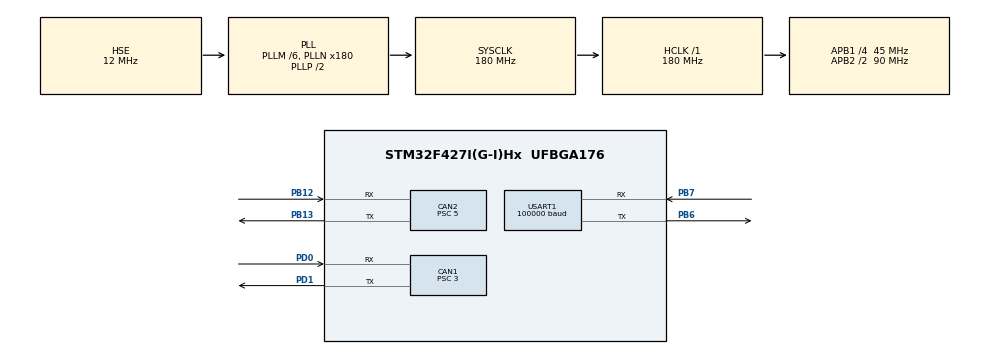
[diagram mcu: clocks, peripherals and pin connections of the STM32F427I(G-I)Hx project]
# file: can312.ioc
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CAN1.BS1=CAN_BS1_7TQ
CAN1.BS2=CAN_BS2_7TQ
CAN1.CalculateBaudRate=1000000
CAN1.CalculateTimeBit=1000
CAN1.CalculateTimeQuantum=66.66666666666666
CAN1.Prescaler=3
CAN2.BS1=CAN_BS1_4TQ
CAN2.BS2=CAN_BS2_4TQ
CAN2.CalculateBaudRate=1000000
CAN2.CalculateTimeBit=1000
CAN2.CalculateTimeQuantum=111.11111111111111
CAN2.Prescaler=5
Dma.Request0=USART1_RX
Dma.USART1_RX.0.Direction=DMA_PERIPH_TO_MEMORY
Dma.USART1_RX.0.FIFOMode=DMA_FIFOMODE_DISABLE
Dma.USART1_RX.0.Instance=DMA2_Stream2
Dma.USART1_RX.0.MemDataAlignment=DMA_MDATAALIGN_BYTE
Dma.USART1_RX.0.MemInc=DMA_MINC_ENABLE
Dma.USART1_RX.0.Mode=DMA_CIRCULAR
Dma.USART1_RX.0.PeriphDataAlignment=DMA_PDATAALIGN_BYTE
Dma.USART1_RX.0.PeriphInc=DMA_PINC_DISABLE
Dma.USART1_RX.0.Priority=DMA_PRIORITY_VERY_HIGH
Mcu.Family=STM32F4
Mcu.Name=STM32F427I(G-I)Hx
Mcu.Package=UFBGA176
NVIC.CAN1_RX0_IRQn=true\:0\:0\:false\:false\:true\:true\:true\:true
NVIC.CAN1_RX1_IRQn=true\:0\:0\:false\:false\:true\:true\:true\:true
NVIC.CAN1_TX_IRQn=true\:0\:0\:false\:false\:true\:true\:true\:true
NVIC.CAN2_RX0_IRQn=true\:0\:0\:false\:false\:true\:true\:true\:true
NVIC.CAN2_RX1_IRQn=true\:0\:0\:false\:false\:true\:true\:true\:true
NVIC.CAN2_TX_IRQn=true\:0\:0\:false\:false\:true\:true\:true\:true
NVIC.DMA2_Stream2_IRQn=true\:0\:0\:false\:false\:true\:false\:true\:true
NVIC.PriorityGroup=NVIC_PRIORITYGROUP_4
NVIC.USART1_IRQn=true\:0\:0\:false\:false\:true\:true\:true\:true
PA13.Mode=Serial_Wire
PA13.Signal=SYS_JTMS-SWDIO
PA14.Mode=Serial_Wire
PA14.Signal=SYS_JTCK-SWCLK
PB12.Mode=CAN_Activate
PB12.Signal=CAN2_RX
PB13.Mode=CAN_Activate
PB13.Signal=CAN2_TX
PB6.Mode=Asynchronous
PB6.Signal=USART1_TX
PB7.Mode=Asynchronous
PB7.Signal=USART1_RX
PD0.Mode=CAN_Activate
PD0.Signal=CAN1_RX
PD1.Mode=CAN_Activate
PD1.Signal=CAN1_TX
PH0/OSC_IN.Mode=HSE-External-Oscillator
PH0/OSC_IN.Signal=RCC_OSC_IN
PH1/OSC_OUT.Mode=HSE-External-Oscillator
PH1/OSC_OUT.Signal=RCC_OSC_OUT
ProjectManager.HeapSize=0x200
ProjectManager.StackSize=0x400
ProjectManager.TargetToolchain=MDK-ARM V5.32
RCC.48MHZClocksFreq_Value=90000000
RCC.AHBFreq_Value=180000000
RCC.APB1CLKDivider=RCC_HCLK_DIV4
RCC.APB1Freq_Value=45000000
RCC.APB1TimFreq_Value=90000000
RCC.APB2CLKDivider=RCC_HCLK_DIV2
RCC.APB2Freq_Value=90000000
RCC.APB2TimFreq_Value=180000000
RCC.CortexFreq_Value=180000000
RCC.HCLKFreq_Value=180000000
RCC.HSE_VALUE=12000000
RCC.HSI_VALUE=16000000
RCC.LSE_VALUE=32768
RCC.PLLM=6
RCC.PLLN=180
RCC.PLLSourceVirtual=RCC_PLLSOURCE_HSE
RCC.SYSCLKFreq_VALUE=180000000
RCC.SYSCLKSource=RCC_SYSCLKSOURCE_PLLCLK
RCC.VCOOutputFreq_Value=360000000
USART1.BaudRate=100000
USART1.Parity=PARITY_EVEN
USART1.VirtualMode=VM_ASYNC
USART1.WordLength=WORDLENGTH_9B
board=custom

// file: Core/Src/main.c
/* USER CODE BEGIN Header */
/**
  ******************************************************************************
  * @file           : main.c
  * @brief          : Main program body
  ******************************************************************************
  * @attention
  *
  * Copyright (c) 2025 STMicroelectronics.
  * All rights reserved.
  *
  * This software is licensed under terms that can be found in the LICENSE file
  * in the root directory of this software component.
  * If no LICENSE file comes with this software, it is provided AS-IS.
  *
  ******************************************************************************
  */
/* USER CODE END Header */
#include "main.h"
#include "can.h"
#include "dma.h"
#include "usart.h"
#include "gpio.h"

/* USER CODE BEGIN Includes */
#include "can-receive.h"
#include "remoter.h"
#include "PID.h"
#include "classic.h"

/* USER CODE END Includes */

/* USER CODE BEGIN PV */

//
//		motor motor2={0,0,0,0};
//		motor motor3={0,0,0,0};
//		motor motor4={0,0,0,0};

/* USER CODE END PV */

void SystemClock_Config(void);

int main(void)
{

  /* MCU Configuration--------------------------------------------------------*/

  /* Reset of all peripherals, Initializes the Flash interface and the Systick. */
  HAL_Init();

  /* Configure the system clock */
  SystemClock_Config();

  /* Initialize all configured peripherals */
  MX_GPIO_Init();
  MX_DMA_Init();
  MX_CAN1_Init();
  MX_USART1_UART_Init();
  MX_CAN2_Init();
  /* USER CODE BEGIN 2 */
  can_filter_init();
	getRemoterMessage();
  //getmessage();
  //motor1.speed_1= (unsigned short) re1.ch1;
	classistask();
  /* USER CODE END 2 */

  /* Infinite loop */
  while (1)
  {

    /* USER CODE BEGIN 3 */

		//speed(&motor1,&motor2,&motor3,&motor4);
//		controlspeed(&motor1,&re1);

  }
  /* USER CODE END 3 */
}

void SystemClock_Config(void)
{
  RCC_OscInitTypeDef RCC_OscInitStruct = {0};
  RCC_ClkInitTypeDef RCC_ClkInitStruct = {0};

  /** Configure the main internal regulator output voltage
  */
  __HAL_RCC_PWR_CLK_ENABLE();
  __HAL_PWR_VOLTAGESCALING_CONFIG(PWR_REGULATOR_VOLTAGE_SCALE1);

  /** Initializes the RCC Oscillators according to the specified parameters
  * in the RCC_OscInitTypeDef structure.
  */
  RCC_OscInitStruct.OscillatorType = RCC_OSCILLATORTYPE_HSE;
  RCC_OscInitStruct.HSEState = RCC_HSE_ON;
  RCC_OscInitStruct.PLL.PLLState = RCC_PLL_ON;
  RCC_OscInitStruct.PLL.PLLSource = RCC_PLLSOURCE_HSE;
  RCC_OscInitStruct.PLL.PLLM = 6;
  RCC_OscInitStruct.PLL.PLLN = 180;
  RCC_OscInitStruct.PLL.PLLP = RCC_PLLP_DIV2;
  RCC_OscInitStruct.PLL.PLLQ = 4;
  if (HAL_RCC_OscConfig(&RCC_OscInitStruct) != HAL_OK)
  {
    Error_Handler();
  }

  /** Activate the Over-Drive mode
  */
  if (HAL_PWREx_EnableOverDrive() != HAL_OK)
  {
    Error_Handler();
  }

  /** Initializes the CPU, AHB and APB buses clocks
  */
  RCC_ClkInitStruct.ClockType = RCC_CLOCKTYPE_HCLK|RCC_CLOCKTYPE_SYSCLK
                              |RCC_CLOCKTYPE_PCLK1|RCC_CLOCKTYPE_PCLK2;
  RCC_ClkInitStruct.SYSCLKSource = RCC_SYSCLKSOURCE_PLLCLK;
  RCC_ClkInitStruct.AHBCLKDivider = RCC_SYSCLK_DIV1;
  RCC_ClkInitStruct.APB1CLKDivider = RCC_HCLK_DIV4;
  RCC_ClkInitStruct.APB2CLKDivider = RCC_HCLK_DIV2;

  if (HAL_RCC_ClockConfig(&RCC_ClkInitStruct, FLASH_LATENCY_5) != HAL_OK)
  {
    Error_Handler();
  }
}

void Error_Handler(void)
{
  __disable_irq();
  while (1)
  {
  }
}
